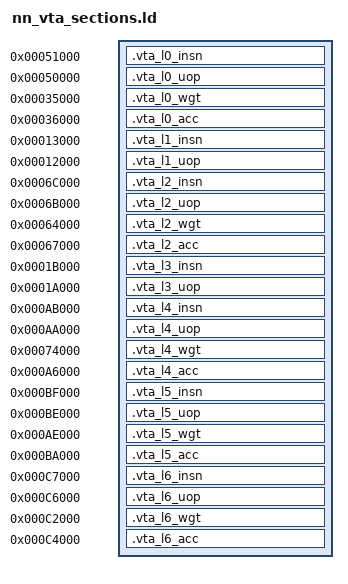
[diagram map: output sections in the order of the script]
/* Auto-generated by gen_nn_baremetal.py - DO NOT EDIT              */
/* VTA static model data linker fragment                             */
/*                                                                   */
/* Include this file inside the platform linker script generated.                    */
/* Example (in your lscript.ld):           */
/*   INCLUDE ../gen/nn_vta_sections.ld                                */

SECTIONS {
.vta_l0_insn 0x00051000 : { KEEP(*(.vta_l0_insn)) }
.vta_l0_uop 0x00050000 : { KEEP(*(.vta_l0_uop)) }
.vta_l0_wgt 0x00035000 : { KEEP(*(.vta_l0_wgt)) }
.vta_l0_acc 0x00036000 : { KEEP(*(.vta_l0_acc)) }
.vta_l1_insn 0x00013000 : { KEEP(*(.vta_l1_insn)) }
.vta_l1_uop 0x00012000 : { KEEP(*(.vta_l1_uop)) }
.vta_l2_insn 0x0006C000 : { KEEP(*(.vta_l2_insn)) }
.vta_l2_uop 0x0006B000 : { KEEP(*(.vta_l2_uop)) }
.vta_l2_wgt 0x00064000 : { KEEP(*(.vta_l2_wgt)) }
.vta_l2_acc 0x00067000 : { KEEP(*(.vta_l2_acc)) }
.vta_l3_insn 0x0001B000 : { KEEP(*(.vta_l3_insn)) }
.vta_l3_uop 0x0001A000 : { KEEP(*(.vta_l3_uop)) }
.vta_l4_insn 0x000AB000 : { KEEP(*(.vta_l4_insn)) }
.vta_l4_uop 0x000AA000 : { KEEP(*(.vta_l4_uop)) }
.vta_l4_wgt 0x00074000 : { KEEP(*(.vta_l4_wgt)) }
.vta_l4_acc 0x000A6000 : { KEEP(*(.vta_l4_acc)) }
.vta_l5_insn 0x000BF000 : { KEEP(*(.vta_l5_insn)) }
.vta_l5_uop 0x000BE000 : { KEEP(*(.vta_l5_uop)) }
.vta_l5_wgt 0x000AE000 : { KEEP(*(.vta_l5_wgt)) }
.vta_l5_acc 0x000BA000 : { KEEP(*(.vta_l5_acc)) }
.vta_l6_insn 0x000C7000 : { KEEP(*(.vta_l6_insn)) }
.vta_l6_uop 0x000C6000 : { KEEP(*(.vta_l6_uop)) }
.vta_l6_wgt 0x000C2000 : { KEEP(*(.vta_l6_wgt)) }
.vta_l6_acc 0x000C4000 : { KEEP(*(.vta_l6_acc)) }
}
